# TF5103_v1 register map
File version: 1.0
Registers are 32-bit, read-write, reset 0x0 unless marked. A register's access mark holds for its fields unless they carry their own. Offsets are from the block's base; [hi:lo] are bit positions; {n}, {i} and the like mark numbered series; 'fields as' and 'values as' point back to an identical list.

## ECAP — ECAP Register Map
Base 0x401B0000
0x00 ECAP_CNT — Input Capture Counter
  [23:0] CNT — Input Capture Timer/Counter (24-bit Up Counter). The input Capture Timer/Counter is a 24-bit up-counting counter. The clock source for the counter is from the clock divider output which the ECAP_CLK is divided by 1, 4, 16, 32, 64, 96, 112 or 128.
{0x4+4i} ECAP_HLD{i} (i=0..2) — Input Capture Counter Hold Register {i}
  [23:0] HOLD — Input Capture Counter Hold Register. When an active input capture channel detects a valid edge signal change, the ECAP_CNT value is latched into the corresponding holding register. Each input channel has itself holding register named by ECAP_HLDx where x is from 0 to 2 to indicate inputs from IC0 to IC2, respectively.
0x10 ECAP_CNTCMP — Input Capture Counter Compare Register
  [23:0] CNTCMP
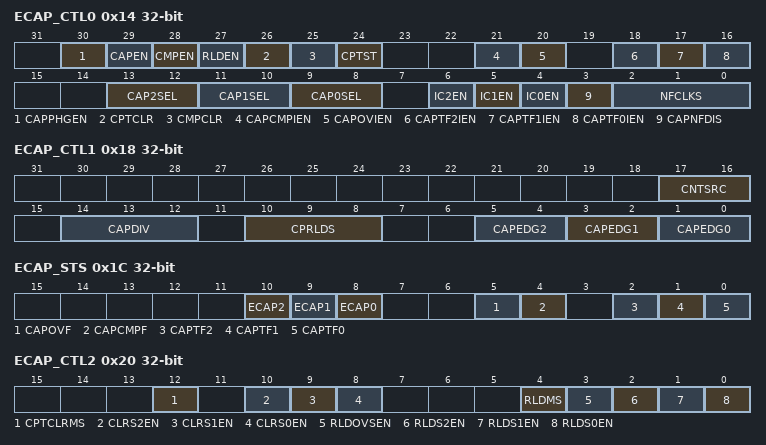
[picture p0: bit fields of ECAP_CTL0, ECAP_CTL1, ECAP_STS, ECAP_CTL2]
0x14 ECAP_CTL0 — Input Capture Control Register 0
  [30] CAPPHGEN — Input Capture Flag Trigger PWM Phase Change Function Enable Control
    0=CAPTF2 or CAPTF1 or CAPTF0 trigger PWM phase change function Disabled; 1=CAPTF2 or CAPTF1 or CAPTF0 trigger PWM phase change function Enabled
  [29] CAPEN — Input Capture Timer/Counter Enable Control
    0=Input Capture function Disabled; 1=Input Capture function Enabled
  [28] CMPEN — The Compare Function Enable Control. The compare function in input capture timer/counter is to compare the dynamic counting ECAP_CNT with the compare register ECAP_CNTCMP, if ECAP_CNT value reaches ECAP_CNTCMP, the flag CAPCMPF will be set.
    0=Compare function Disabled; 1=Compare function Enabled
  [27] RLDEN — The Reload Function Enable Control. Setting this bit to enable reload function. If the reload control is enabled, an overflow event (CAPOVF) or capture events (CAPTFx) will trigger the hardware to reload ECAP_CNTCMP into ECAP_CNT.
    0=Reload function Disabled; 1=Reload function Enabled
  [26] CPTCLR — Input Capture Counter Clear by Capture Events Control. If this bit is set to 1, the capture counter (ECAP_CNT) will be cleared to 0 when any one of capture events (CAPTF0~3) occurs.
    0=Capture events (CAPTF0~3) can clear capture counter (ECAP_CNT) Disabled; 1=Capture events (CAPTF0~3) can clear capture counter (ECAP_CNT) Enabled
  [25] CMPCLR — Input Capture Counter Clear by Compare-match Control
    0=Compare-match event (CAMCMPF) can clear capture counter (ECAP_CNT) Disabled; 1=Compare-match event (CAMCMPF) can clear capture counter (ECAP_CNT) Enabled
  [24] CPTST — Input Capture Counter Start Bit. Setting this bit to 1, the capture counter (ECAP_CNT) starts up-counting synchronously with capture clock input (ECAP_CLK).
    0=ECAP_CNT stop counting; 1=ECAP_CNT starts up-counting
  [21] CAPCMPIEN — Enable CAPCMPF Trigger Input Capture Interrupt
    0=Disabling flag CAPCMPF can trigger Input Capture interrupt; 1=Enabling flag CAPCMPF can trigger Input Capture interrupt
  [20] CAPOVIEN — Enable CAPOVF Trigger Input Capture Interrupt
    0=Disabling flag CAPOVF can trigger Input Capture interrupt; 1=Enabling flag CAPOVF can trigger Input Capture interrupt
  [18] CAPTF2IEN — Enable Input Capture Channel 2 Interrupt
    0=Disabling flag CAPTF2 can trigger Input Capture interrupt; 1=Enabling flag CAPTF2 can trigger Input Capture interrupt
  [17] CAPTF1IEN — Enable Input Capture Channel 1 Interrupt
    0=Disabling flag CAPTF1 can trigger Input Capture interrupt; 1=Enabling flag CAPTF1 can trigger Input Capture interrupt
  [16] CAPTF0IEN — Enable Input Capture Channel 0 Interrupt
    0=Disabling flag CAPTF0 can trigger Input Capture interrupt; 1=Enabling flag CAPTF0 can trigger Input Capture interrupt
  [13:12] CAP2SEL — CAP2 Input Source Selection
    0=CAP2 input is from port pin ECAP_P2; 1=CAP2 input is from signal ACMP_CO0 (Analog comparator 0 output); 2=CAP2 input is from signal ACMP_CO1 (Analog comparator 1 output); 3=CAP2 input is from signal ADC_ECAP (ADC compare output)
  [11:10] CAP1SEL — CAP1 Input Source Selection
    0=CAP1 input is from port pin ECAP_P1; 1=CAP1 input is from signal ACMP_CO0 (Analog comparator 0 output); 2=CAP1 input is from signal ACMP_CO1 (Analog comparator 1 output); 3=CAP1 input is from signal ADC_ECAP (ADC compare output)
  [9:8] CAP0SEL — CAP0 Input Source Selection
    0=CAP0 input is from port pin ECAP_P0; 1=CAP0 input is from signal ACMP_CO0 (Analog comparator 0 output); 2=CAP0 input is from signal ACMP_CO1 (Analog comparator 1 output); 3=CAP0 input is from signal ADC_ECAP (ADC compare output)
  [6] IC2EN — Enable Port Pin IC2 Input to Input Capture Unit
    0=IC2 input to Input Capture Unit Disabled; 1=IC2 input to Input Capture Unit Enabled
  [5] IC1EN — Enable Port Pin IC1 Input to Input Capture Unit
    0=IC1 input to Input Capture Unit Disabled; 1=IC1 input to Input Capture Unit Enabled
  [4] IC0EN — Enable Port Pin IC0 Input to Input Capture Unit
    0=IC0 input to Input Capture Unit Disabled; 1=IC0 input to Input Capture Unit Enabled
  [3] CAPNFDIS — Disable Input Capture Noise Filter
    0=Noise filter of Input Capture Enabled; 1=The noise filter of Input Capture Disabled
  [2:0] NFCLKS — Noise Filter Clock Pre-divided Selection. To determine the sampling frequency of the Noise Filter clock
    0=ECAP_CLK; 1=ECAP_CLK / 2; 2=ECAP_CLK / 4; 3=ECAP_CLK / 16; 4=ECAP_CLK / 32; 5=ECAP_CLK / 64; 6=ECAP_CLK / 128; 7=ECAP_CLK / 256
0x18 ECAP_CTL1 — Input Capture Control Register 1
  [17:16] CNTSRC — Capture Timer/Counter Clock Source Selection. Select the capture timer/counter clock source
    0=ECAP_CLK (Default); 1=CAP0; 2=CAP1; 3=CAP2
  [14:12] CAPDIV — Capture Timer Clock Divide Selection. The capture timer clock has a pre-divider with four divided options controlled by CAPDIV[2:0].
    0=ECAP_CLK / 1; 1=ECAP_CLK / 4; 2=ECAP_CLK / 16; 3=ECAP_CLK / 32; 4=ECAP_CLK / 64; 5=ECAP_CLK / 96; 6=ECAP_CLK / 112; 7=ECAP_CLK / 128
  [10:8] CPRLDS — ECAP_CNT Reload Trigger Source Selection
    0=CAPTF0; 1=CAPTF1; 2=CAPTF2; 4=CAPOVF
  [5:4] CAPEDG2 — Channel 2 Captured Edge Selection. Input capture can detect falling edge change only, rising edge change only or one of both edge change
    0=Detect rising edge; 1=Detect falling edge; 2=Detect either rising or falling edge
  [3:2] CAPEDG1 — Channel 1 Captured Edge Selection. Input capture can detect falling edge change only, rising edge change only or one of both edge change
    values as CAPEDG2
  [1:0] CAPEDG0 — Channel 0 Captured Edge Selection. Input capture can detect falling edge change only, rising edge change only or one of both edge change
    values as CAPEDG2
0x1C ECAP_STS — Input Capture Status Register
  [10] ECAP2 ro — Input Capture Source 2 Status (Read Only). Input captureSource 2 (ECAP_P2) status. It is read only. (The bit is read only and write is ignored)
  [9] ECAP1 ro — Input Capture Source 1 Status (Read Only). Input capture Source 1 (ECAP_P1) status. It is read only. (The bit is read only and write is ignored)
  [8] ECAP0 ro — Input Capture Source 0 Status (Read Only). Input capture Source 0 (ECAP_P0) status. It is read only. (The bit is read only and write is ignored)
  [5] CAPOVF — Input Capture Counter Overflow Flag. Flag is set by hardware when input capture up counter (CNT) overflows from 0x00FF_FFFF to 0. Note: This bit is only cleared by writing 1 to itself through software.
    0=No overflow occurs in CNT; 1=CNT overflows
  [4] CAPCMPF — Input Capture Compare-match Flag. If the input capture compare function is enabled, the flag is set by hardware while capture counter (CNT) up counts and reach to the CNTCMP value. Note: This bit is only cleared by writing 1 to itself through software.
    0=CNT does not match with CNTCMP value; 1=CNT counts to the same as CNTCMP value
  [2] CAPTF2 — Input Capture Channel 2 Captured Flag. When the input capture channel 2 detects a valid edge change at CAP2 input, it will set flag CAPTF2 to high. Note: This bit is only cleared by writing 1 to itself through software.
    0=No valid edge change is detected at CAP2 input; 1=A valid edge change is detected at CAP2 input
  [1] CAPTF1 — Input Capture Channel 1 Captured Flag. When the input capture channel 1 detects a valid edge change at CAP1 input, it will set flag CAPTF1 to high. Note: This bit is only cleared by writing 1 to itself through software.
    0=No valid edge change is detected at CAP1 input; 1=A valid edge change is detected at CAP1 input
  [0] CAPTF0 — Input Capture Channel 0 Captured Flag. When the input capture channel 0 detects a valid edge change at CAP0 input, it will set flag CAPTF0 to high. Note: This bit is only cleared by writing 1 to itself through software.
    0=No valid edge change is detected at CAP0 input; 1=A valid edge change is detected at CAP0 input
0x20 ECAP_CTL2 — Input Capture Control Register 2
  [12] CPTCLRMS — CPTCLR Function Trigger Event Source Mode Selection
    0=CPTCLR event source in normal mode; 1=CPTCLR event source in enhanced mode
  [10] CLRS2EN — CAPTF2 Event Trigger Enable For CPTCLR event Source
    0=Disabling flag CAPTF2 can trigger CPTCLR function; 1=Enabling flag CAPTF2 can trigger CPTCLR function
  [9] CLRS1EN — CAPTF1 Event Trigger Enable For CPTCLR event Source
    0=Disabling flag CAPTF1 can trigger CPTCLR function; 1=Enabling flag CAPTF1 can trigger CPTCLR function
  [8] CLRS0EN — CAPTF0 Event Trigger Enable For CPTCLR event Source
    0=Disabling flag CAPTF0 can trigger CPTCLR function; 1=Enabling flag CAPTF0 can trigger CPTCLR function
  [4] RLDMS — RLD Function Trigger Event Source Mode Selection
    0=RLD event source in normal mode; 1=RLD event source in enhanced mode
  [3] RLDOVSEN — CAPOVF Event Trigger Enable For RLD event Source
    0=Disabling flag CAPOVF can trigger RLD function; 1=Enabling flag CAPOVF can trigger RLD function
  [2] RLDS2EN — CAPTF2 Event Trigger Enable For RLD event Source
    0=Disabling flag CAPTF2 can trigger RLD function; 1=Enabling flag CAPTF2 can trigger RLD function
  [1] RLDS1EN — CAPTF1 Event Trigger Enable For RLD event Source
    0=Disabling flag CAPTF1 can trigger RLD function; 1=Enabling flag CAPTF1 can trigger RLD function
  [0] RLDS0EN — CATF0 Event Trigger Enable For RLD event Source
    0=Disabling flag CAPTF0 can trigger RLD function; 1=Enabling flag CAPTF0 can trigger RLD function
